# FM33FK5XX register map
File version: 1.0
CPU: Cortex-M33 r1p0, little endian, MPU, FPU, 3 interrupt priority bits
Registers are 32-bit, read-write, reset 0x0 unless marked. A register's access mark holds for its fields unless they carry their own. Offsets are from the block's base; [hi:lo] are bit positions; {n}, {i} and the like mark numbered series.

## PGL — PGL module information
Base 0x4001DC00
0x00 CR
  [3:0] LUTEN — LUTEN field description
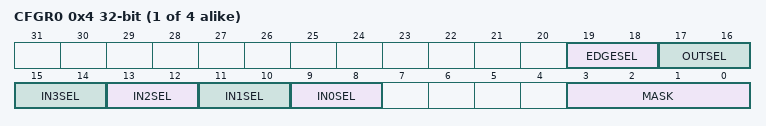
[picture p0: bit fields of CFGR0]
{0x4+4i} CFGR{i} (i=0..3)
  [19:18] EDGESEL — EDGESEL field description
  [17:16] OUTSEL — OUTSEL field description
  [2n+9:2n+8] IN{n}SEL (n=0..3) — IN{n}SEL field description
  [3:0] MASK — MASK field description
0x14 IER
  [3:0] LUTIE — LUTIE field description
0x18 ISR
  [3:0] LUTIF — LUTIF field description
{0x1C+4i} LUT{i} (i=0..3)
  [15:0] TRUTH — TRUTH field description

## USBPHY — USBPHY module information
Base 0x50010000
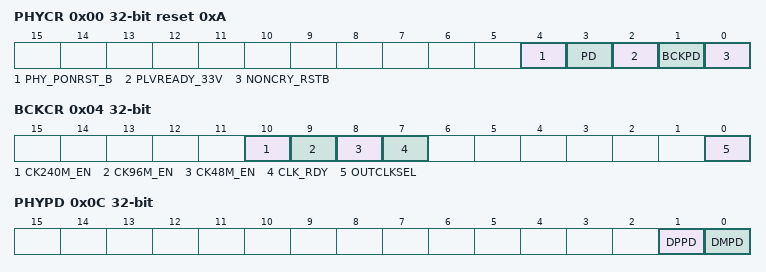
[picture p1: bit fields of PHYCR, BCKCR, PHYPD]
0x00 PHYCR reset 0xA
  [4] PHY_PONRST_B — PHY_PONRST_B field description
  [3] PD — PD field description
  [2] PLVREADY_33V — PLVREADY_33V field description
  [1] BCKPD — BCKPD field description
  [0] NONCRY_RSTB — NONCRY_RSTB field description
0x04 BCKCR access per field
  [10] CK240M_EN rw — CK240M_EN field description
  [9] CK96M_EN rw — CK96M_EN field description
  [8] CK48M_EN rw — CK48M_EN field description
  [7] CLK_RDY ro — CLK_RDY field description
  [0] OUTCLKSEL rw — OUTCLKSEL field description
0x08 PHYTEST reset 0x1
  [1:0] PHYBIST — PHYBIST field description
0x0C PHYPD
  [1] DPPD — DPPD field description
  [0] DMPD — DMPD field description

## GPIOA — GPIOA module information
Base 0x40000C00
0x00 INEN — GPIOAInputEnableRegister
  [15:0] PxINEN — PxINEN field description
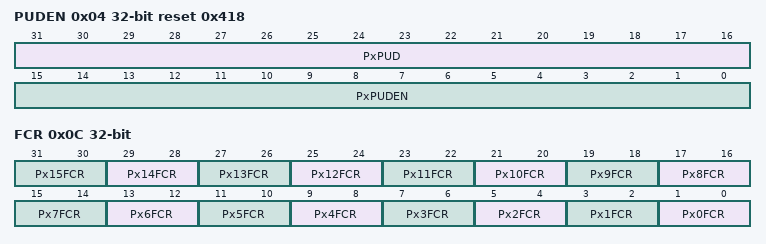
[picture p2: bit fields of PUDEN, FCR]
0x04 PUDEN reset 0x418 — GPIOAPull-UpPull-DownEnableRegister
  [31:16] PxPUD — PxPUD field description
  [15:0] PxPUDEN — PxPUDEN field description
0x08 ODEN — GPIOAOpen-DrainEnableRegister
  [15:0] PxODEN — PxODEN field description
0x0C FCR — GPIOAFunctionControlRegister
  [2n+1:2n] Px{n}FCR (n=0..15) — Px{n}FCR field description
0x10 DO — GPIOADataOutputRegister
  [15:0] PxDO — PxDO field description
0x14 DSET wo — GPIOADataSetRegister
  [15:0] PxSET — PxSET field description
0x18 DRST wo — GPIOADataResetRegister
  [15:0] PxRESET — PxRESET field description
0x1C DIN ro — GPIOADataInputRegister
  [15:0] PxDIN — PxDIN field description
0x20 DFS — GPIOADigitalFunctionSelect
  [31:0] PxDFS — PxDFS field description
0x28 ANEN — GPIOAAnalogchannelEnableRegister
  [15:0] PxANEN — PxANEN field description
0x2C DSR reset 0x55005555 — GPIOADriverStrengthRegister
  [31:0] PxDS — PxDS field description

## GPIOB — GPIOB module information
Base 0x40000C40
Same registers: GPIOC 0x40000C80, GPIOD 0x40000CC0, GPIOE 0x40000D00, GPIOF 0x40000D40
Registers as GPIOA (with GPIOA read as GPIOB), without PUDEN; these are added or differ:
0x08 ODEN — GPIOBOpeb-DrainEnableRegister
  [15:0] PxODEN — PxODEN field description

## GPIO — GPIO module information
Base 0x40000DC0
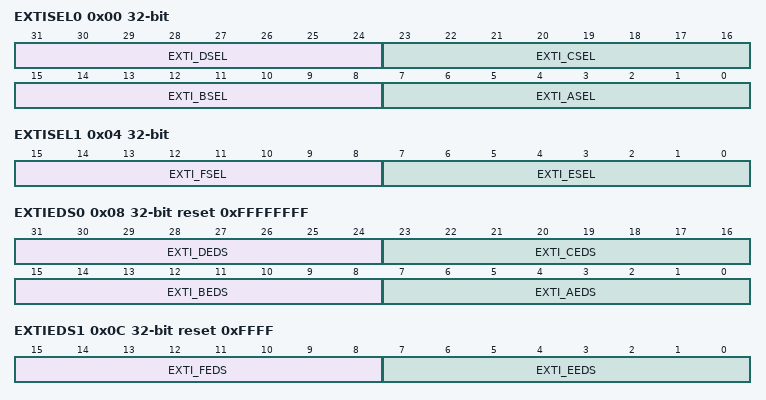
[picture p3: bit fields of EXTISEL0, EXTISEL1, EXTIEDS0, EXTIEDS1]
0x00 EXTISEL0 — ExternalInterruptInputSelectRegister0
  [31:24] EXTI_DSEL — EXTI_DSEL field description
  [23:16] EXTI_CSEL — EXTI_CSEL field description
  [15:8] EXTI_BSEL — EXTI_BSEL field description
  [7:0] EXTI_ASEL — EXTI_ASEL field description
0x04 EXTISEL1 — ExternalInterruptInputSelectRegister1
  [15:8] EXTI_FSEL — EXTI_FSEL field description
  [7:0] EXTI_ESEL — EXTI_ESEL field description
0x08 EXTIEDS0 reset 0xFFFFFFFF — ExternalInterruptEdgeSelectandEnableRegister0
  [31:24] EXTI_DEDS — EXTI_DEDS field description
  [23:16] EXTI_CEDS — EXTI_CEDS field description
  [15:8] EXTI_BEDS — EXTI_BEDS field description
  [7:0] EXTI_AEDS — EXTI_AEDS field description
0x0C EXTIEDS1 reset 0xFFFF — ExternalInterruptEdgeSelectandEnableRegister1
  [15:8] EXTI_FEDS — EXTI_FEDS field description
  [7:0] EXTI_EEDS — EXTI_EEDS field description
0x10 EXTIDF — ExternalInterruptDigitalFilterRegister
  [22:0] EXTI_DF — EXTI_DF field description
0x14 EXTIISR — ExternalInterruptandStatusRegister
  [22:0] EXTI — EXTI field description
0x18 EXTIDI — ExternalInterruptDataInputRegister
  [22:0] EXTI_DI — EXTI_DI field description
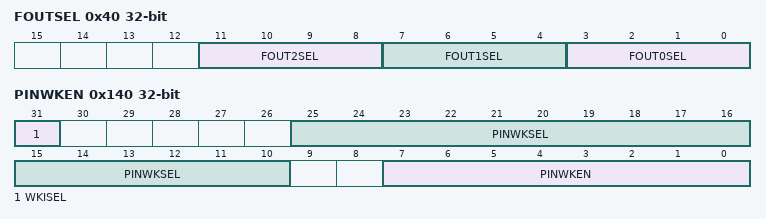
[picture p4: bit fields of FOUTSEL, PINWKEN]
0x40 FOUTSEL — FrequencyOutputSelectRegister
  [11:8] FOUT2SEL — FOUT2SEL field description
  [7:4] FOUT1SEL — FOUT1SEL field description
  [3:0] FOUT0SEL — FOUT0SEL field description
0x140 PINWKEN — WakeupEnableRegister
  [31] WKISEL — WKISEL field description
  [25:10] PINWKSEL — PINWKSEL field description
  [7:0] PINWKEN — PINWKEN field description
